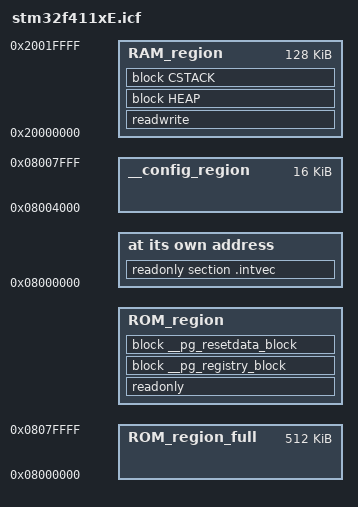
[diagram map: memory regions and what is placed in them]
/*###ICF### Section handled by ICF editor, don't touch! ****/
/*-Editor annotation file-*/
/* IcfEditorFile="$TOOLKIT_DIR$\config\ide\IcfEditor\cortex_v1_0.xml" */
/*-Specials-*/
define symbol __ICFEDIT_intvec_start__ = 0x08000000;
/*-Memory Regions-*/
define symbol __ICFEDIT_region_ROM_start__ = 0x08000000;
define symbol __ICFEDIT_region_ROM_end__   = 0x0807FFFF;
define symbol __ICFEDIT_region_RAM_start__ = 0x20000000;
define symbol __ICFEDIT_region_RAM_end__   = 0x2001FFFF;
/*-Sizes-*/
define symbol __ICFEDIT_size_cstack__ = 0x2000;
define symbol __ICFEDIT_size_heap__   = 0x2000;
/**** End of ICF editor section. ###ICF###*/

define memory mem with size = 4G;

define block CSTACK    with alignment = 8, size = __ICFEDIT_size_cstack__   { };
define block HEAP      with alignment = 8, size = __ICFEDIT_size_heap__     { };

initialize by copy { readwrite };
do not initialize  { section .noinit };

place at address mem:__ICFEDIT_intvec_start__ { readonly section .intvec };

/*EEPROM section named "config"*/
define exported symbol __config_start 		= __ICFEDIT_region_ROM_start__ + 16k;
define exported symbol __config_end   		= __config_start + 16k - 1;
define region 		   __config_region   	= mem:[from __config_start to __config_end];

/*pg_registry*/
define block           __pg_registry_block with alignment=4
	{ 
		section .pg_registry 
	};

/*__pg_resetdata*/
define block           __pg_resetdata_block with alignment=2
	{ 
		section .pg_resetdata 
	};


/* FLASH arrea */
define region ROM_region_full   = mem:[from __ICFEDIT_region_ROM_start__   to __ICFEDIT_region_ROM_end__];
define region ROM_region		= ROM_region_full - __config_region;
place in 	  ROM_region   
	{ 
		readonly,
		block __pg_registry_block,
		block __pg_resetdata_block
	};

/* RAM arrea*/
define region RAM_region   = mem:[from __ICFEDIT_region_RAM_start__   to __ICFEDIT_region_RAM_end__];
place in      RAM_region   
	{ 
		readwrite,
		block HEAP, 
        block CSTACK 
	};


define exported symbol _Hot_Reboot_Flags_Size = 16;
define exported symbol _Min_Stack_Size   	 = __ICFEDIT_size_cstack__;
define exported symbol _estack   			 = 0x08000000;
define exported symbol isr_vector_table_base  = 0x08000000;

